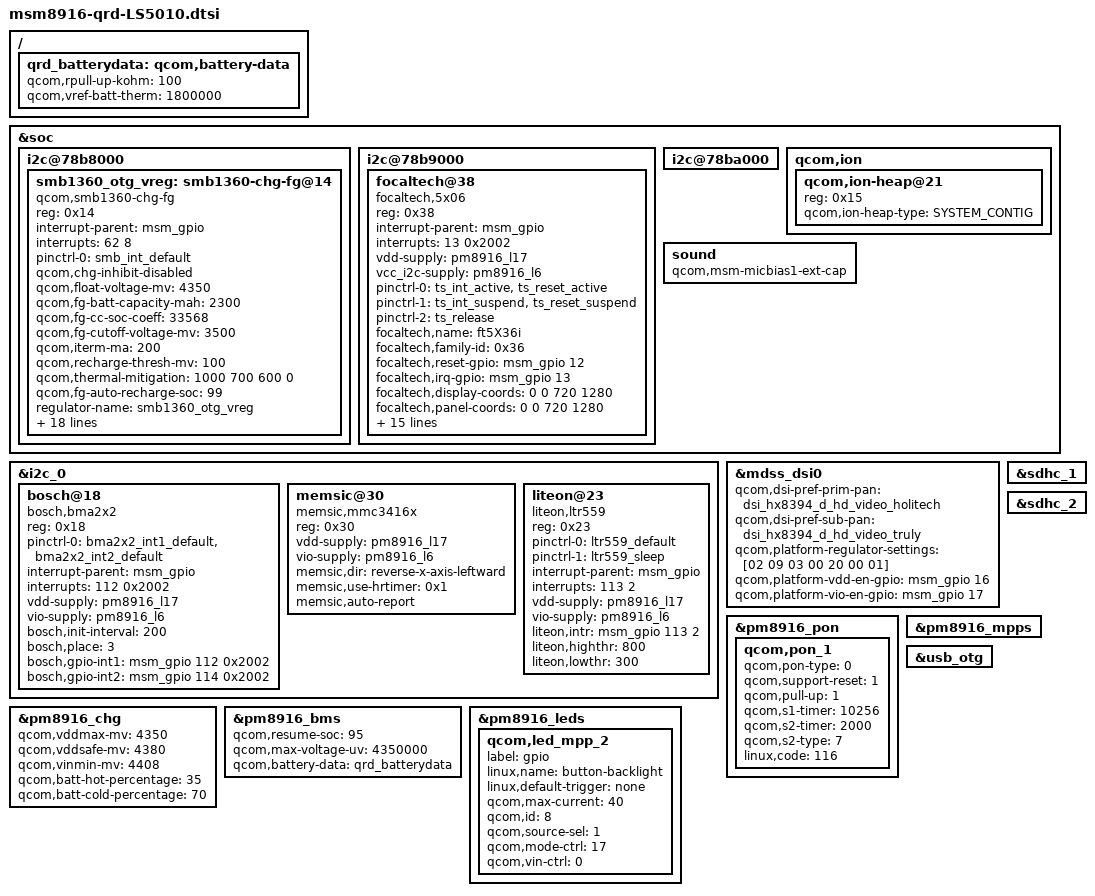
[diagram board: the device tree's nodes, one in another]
/* Copyright (c) 2020, The Linux Foundation. All rights reserved.
*  Copyright (c) 2020, the_shahnawaz_sheikh (sheikhshahnawaz41299).
*
* This program is free software; you can redistribute it and/or modify
* it under the terms of the GNU General Public License version 2 and
* only version 2 as published by the Free Software Foundation.
*
* This program is distributed in the hope that it will be useful,
* but WITHOUT ANY WARRANTY; without even the implied warranty of
* MERCHANTABILITY or FITNESS FOR A PARTICULAR PURPOSE.  See the
* GNU General Public License for more details.
*/

#include "dsi-panel-hx8394-d-hd-video-holitech.dtsi"
#include "dsi-panel-hx8394-d-hd-video-truly.dtsi"
#include "dsi-panel-hx8394-f-hd-video-bitland.dtsi"
#include "msm8916-camera-sensor-qrd-skui-LS5010.dtsi"
#include "msm8916-pinctrl-LS5010.dtsi"

&soc {
    
	i2c@78b8000 {
	  
	 /delete-node/ smb1360-chg-fg@14;
	
	 smb1360_otg_vreg: smb1360-chg-fg@14 {
				compatible = "qcom,smb1360-chg-fg";
				reg = <0x14>;
				interrupt-parent = <&msm_gpio>;
				interrupts = <62 8>;
				pinctrl-names = "default";
				pinctrl-0 = <&smb_int_default>;
				qcom,chg-inhibit-disabled;
				qcom,float-voltage-mv = <4350>;
				qcom,fg-batt-capacity-mah = <2300>;
				qcom,fg-cc-soc-coeff = <33568>;
				qcom,fg-cutoff-voltage-mv = <3500>;
				qcom,iterm-ma = <200>;
				qcom,recharge-thresh-mv = <100>;
				qcom,thermal-mitigation = <1000 700 600 0>;
				qcom,fg-auto-recharge-soc = <99>;
				regulator-name = "smb1360_otg_vreg";
				qcom,fg-delta-soc_reg = <1>;
				qcom,empty-soc-disabled;
				qcom,charging-led = <&msm_gpio 22 0>;
				qcom,otg-batt-curr-limit = <1500>;
				qcom,fg-reset-at-pon;
				qcom,fg-reset-thresold-mv = <100>;
				qcom,shdn-after-pwroff;
				qcom,config-hard-thresholds;
				qcom,hot-bat-decidegc = <600>;
				qcom,cold-bat-decidegc = <0>;
				qcom,soft-jeita-supported;
				qcom,warm-bat-decidegc = <450>;
				qcom,cool-bat-decidegc = <100>;
				qcom,cool-bat-mv = <4340>;
				qcom,warm-bat-mv = <4330>;
				qcom,cool-bat-ma = <450>;
				qcom,warm-bat-ma = <600>;
				qcom,thermistor-c1-coeff = <34522>;
			};
	
	};
	

	i2c@78b9000 { /* BLSP1 QUP5 */
	     
		/delete-node/ focaltech@38;
		
		focaltech@38 {
				compatible = "focaltech,5x06";
				reg = <0x38>;
				interrupt-parent = <&msm_gpio>;
				interrupts = <13 0x2002>;
				vdd-supply = <&pm8916_l17>;
			    vcc_i2c-supply = <&pm8916_l6>;
				pinctrl-names = "pmx_ts_active", "pmx_ts_suspend", "pmx_ts_release";
				pinctrl-0 = <&ts_int_active &ts_reset_active>;
			    pinctrl-1 = <&ts_int_suspend &ts_reset_suspend>;
			    pinctrl-2 = <&ts_release>;
				focaltech,name = "ft5X36i";
				focaltech,family-id = <0x36>;
				focaltech,reset-gpio = <&msm_gpio 12 0>;
				focaltech,irq-gpio = <&msm_gpio 13 0x2002>;
				focaltech,display-coords = <0 0 720 1280>;
				focaltech,panel-coords = <0 0 720 1280>;
				focaltech,virtual_key;
				focaltech,no-force-update;
				focaltech,i2c-pull-up;
				focaltech,group-id = <1>;
				focaltech,hard-reset-delay-ms = <20>;
				focaltech,soft-reset-delay-ms = <300>;
				focaltech,num-max-touches = <5>;
				focaltech,fw-delay-aa-ms = <30>;
				focaltech,fw-delay-55-ms = <30>;
				focaltech,fw-upgrade-id1 = <0x79>;
				focaltech,fw-upgrade-id2 = <0x18>;
				focaltech,fw-delay-readid-ms = <10>;
				focaltech,fw-delay-era-flsh-ms = <2000>;
				focaltech,ignore-id-check;
				focaltech,keep-pwr-suppend;
			};
	};
      
    i2c@78ba000 {
           /delete-node/ nfc-nci@e;
     };
	
	qcom,ion {
	   
	   qcom,ion-heap@21 {
				reg = <0x15>;
				qcom,ion-heap-type = "SYSTEM_CONTIG";
			};
	};
	
	sound {
	  
	  qcom,msm-micbias1-ext-cap;
	 
	};

	
};

&i2c_0 { /* BLSP1 QUP2 */

	bosch@18 { /* Accelerometer sensor */
		compatible = "bosch,bma2x2";
		reg = <0x18>;
		pinctrl-names = "default";
		pinctrl-0 = <&bma2x2_int1_default &bma2x2_int2_default>;
		interrupt-parent = <&msm_gpio>;
		interrupts = <112 0x2002>;
		vdd-supply = <&pm8916_l17>;
		vio-supply = <&pm8916_l6>;
		bosch,init-interval = <200>;
		bosch,place = <3>;
		bosch,gpio-int1 = <&msm_gpio 112 0x2002>;
		bosch,gpio-int2 = <&msm_gpio 114 0x2002>;
		status = "ok";
	};

	memsic@30 { /* Magnetic field sensor */
		compatible = "memsic,mmc3416x";
		reg = <0x30>;
		vdd-supply = <&pm8916_l17>;
		vio-supply = <&pm8916_l6>;
		memsic,dir = "reverse-x-axis-leftward";
		memsic,use-hrtimer = <0x1>;
		memsic,auto-report;
		status = "ok";
	};
	
	liteon@23 {
				compatible = "liteon,ltr559";
				reg = <0x23>;
				pinctrl-names = "default", "sleep";
				pinctrl-0 = <&ltr559_default>;
				pinctrl-1 = <&ltr559_sleep>;
				interrupt-parent = <&msm_gpio>;
				interrupts = <113 2>;
				vdd-supply = <&pm8916_l17>;
		        vio-supply = <&pm8916_l6>;
				liteon,intr = <&msm_gpio 113 2>;
				liteon,highthr = <800>;
				liteon,lowthr = <300>;
				status = "ok";
			};
			
	

};


&mdss_dsi0 {
	qcom,dsi-pref-prim-pan = <&dsi_hx8394_d_hd_video_holitech>;
	
	qcom,dsi-pref-sub-pan = <&dsi_hx8394_d_hd_video_truly>;
	
	qcom,platform-regulator-settings = [02 09 03 00 20 00 01];
	
    qcom,platform-vdd-en-gpio = <&msm_gpio 16 0>;
	qcom,platform-vio-en-gpio = <&msm_gpio 17 0>;

};

/ {
	qrd_batterydata: qcom,battery-data {
	   qcom,rpull-up-kohm = <100>;
		qcom,vref-batt-therm = <1800000>;
		
		#include "batterydata-qrd-4v35-2300mah.dtsi"
		
	};
};

&sdhc_1 {
};

&sdhc_2 {
};

&pm8916_pon {
    qcom,pon_1 {
				qcom,pon-type = <0>;
				qcom,support-reset = <1>;
				qcom,pull-up = <1>;
				qcom,s1-timer = <10256>;
				qcom,s2-timer = <2000>;
				qcom,s2-type = <7>;
				linux,code = <116>;
			};
};

&pm8916_mpps {
};
   
   

&pm8916_chg {
  status = "ok";
  qcom,vddmax-mv = <4350>;
  qcom,vddsafe-mv = <4380>;
  qcom,vinmin-mv = <4408>;
  qcom,batt-hot-percentage = <35>;
  qcom,batt-cold-percentage = <70>;
  
};

&pm8916_bms {
	status = "ok";
	/delete-property/ qcom,disable-bms;
	qcom,resume-soc = <95>;
	qcom,max-voltage-uv = <4350000>;
	qcom,battery-data = <&qrd_batterydata>;
};

&pm8916_leds {
    status = "okay";

		qcom,led_mpp_2 {
				label = "gpio";
				linux,name = "button-backlight";
				linux,default-trigger = "none";
				qcom,max-current = <40>;
				qcom,id = <8>;
				qcom,source-sel = <1>;
				qcom,mode-ctrl = <17>;
				qcom,vin-ctrl = <0>;
		};
};

&usb_otg {
  /delete-property/ qcom,hsusb-otg-disable-reset;
};








